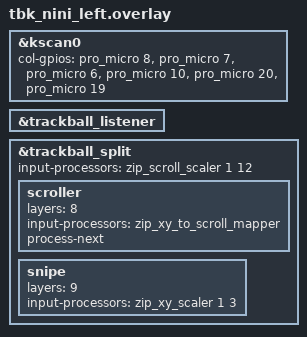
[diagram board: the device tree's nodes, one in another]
/*
 * Copyright (c) 2020 Pete Johanson
 *
 * SPDX-License-Identifier: MIT
 */

#include "tbk_nini.dtsi"
#include <zephyr/dt-bindings/input/input-event-codes.h>
#include <input/processors.dtsi>

&kscan0 {
    col-gpios
      = <&pro_micro 8 GPIO_ACTIVE_HIGH>
      , <&pro_micro 7 GPIO_ACTIVE_HIGH>
      , <&pro_micro 6 GPIO_ACTIVE_HIGH>
      , <&pro_micro 10 GPIO_ACTIVE_HIGH>
      , <&pro_micro 20 GPIO_ACTIVE_HIGH>
      , <&pro_micro 19 GPIO_ACTIVE_HIGH>
      ;
};

&trackball_listener{
  status = "okay";
};

&trackball_split {
  // Input processors
  input-processors = <&zip_xy_scaler 3 2>;
  input-processors = <&zip_scroll_scaler 1 12>;
  scroller {
    layers = <8>;
    input-processors = <&zip_xy_to_scroll_mapper>;
    process-next;
  };

  snipe {
    layers = <9>;
    input-processors = <&zip_xy_scaler 1 3>;
  };
  // end of Input processors
};
